# ExynosT100 register map
Vendor: SAMSUNG System LSI; Series: ARMCM4F; File version: 0.1
CPU: CM4 r1p0, little endian, MPU, FPU, 3 interrupt priority bits
Registers are 32-bit, read-write, reset 0x0 unless marked. A register's access mark holds for its fields unless they carry their own. Offsets are from the block's base; [hi:lo] are bit positions; {n}, {i} and the like mark numbered series.

## CRC — CRC Calculators
Base 0x40010000
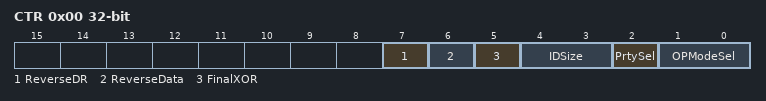
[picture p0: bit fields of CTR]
0x00 CTR — CRC Calculation Control Register
  [7] ReverseDR — Reverse CRC Result before Final XOR
  [6] ReverseData — Reverse Data Byte
  [5] FinalXOR — CRC final XOR value control 0 = Final XOR value is 0x0000_0000 1 = Final XOR value is 0xFFFF_FFFF (CRC32) or 0xFFFF (CRC16)
  [4:3] IDSize — These bits are used to select the size of input data
  [2] PrtySel — Parity Mode Control
  [1:0] OPModeSel — This bit is used to select CRC
0x04 IDR wo — Offset: 0x0004 Input data register
  [31:0] Value — These bits are input data to calculate the CRC bits
0x08 DR — Offset: 0x0008 data register
  [31:0] Value — These bits are output data buffer for calculate CRC before post processing.
0x0C ODR ro — Offset: 0x000C Output data register
  [31:0] Value — CRC bits that is calculated by hardware

## GPIO — General-Purpose Input Output
Base 0x40023000
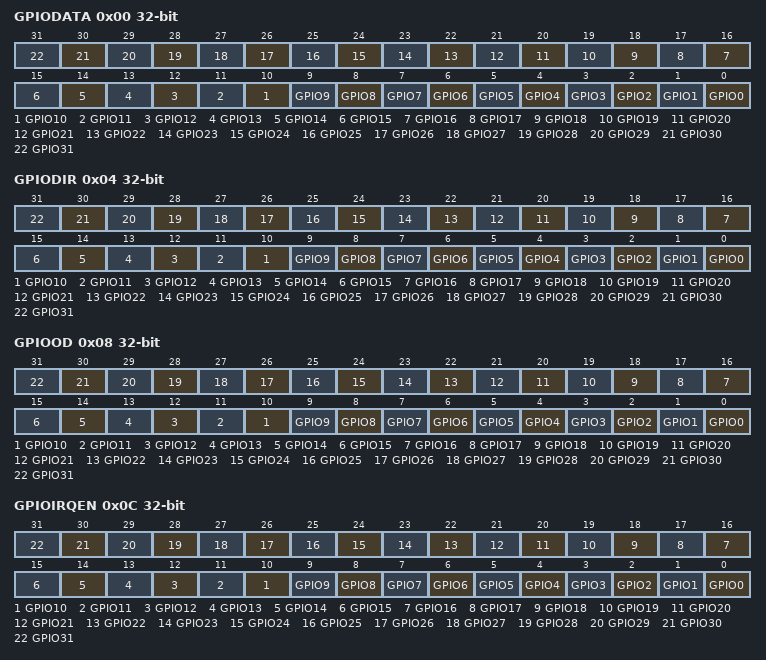
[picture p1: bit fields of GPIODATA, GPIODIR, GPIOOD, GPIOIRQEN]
0x00 GPIODATA — Read current state or set GPIO pins Input mode 0 = Associated GPIO is low 1 = Associated GPIO is high Output mode 0 = Set associated GPIO to low 1 = Set associated GPIO to high
  [n] GPIO{n} (n=0..31)
0x04 GPIODIR — Configure GPIO direction 0 = Input mode 1 = Output mode
  [n] GPIO{n} (n=0..31)
0x08 GPIOOD — GPIO n output type selection bit 0 = Set output type to push-pull mode 1 = Set output type to open-drain mode
  [n] GPIO{n} (n=0..31)
0x0C GPIOIRQEN — GPIO n interrupt enable bit 0 = IRQ disable 1 = IRQ enable
  [n] GPIO{n} (n=0..31)
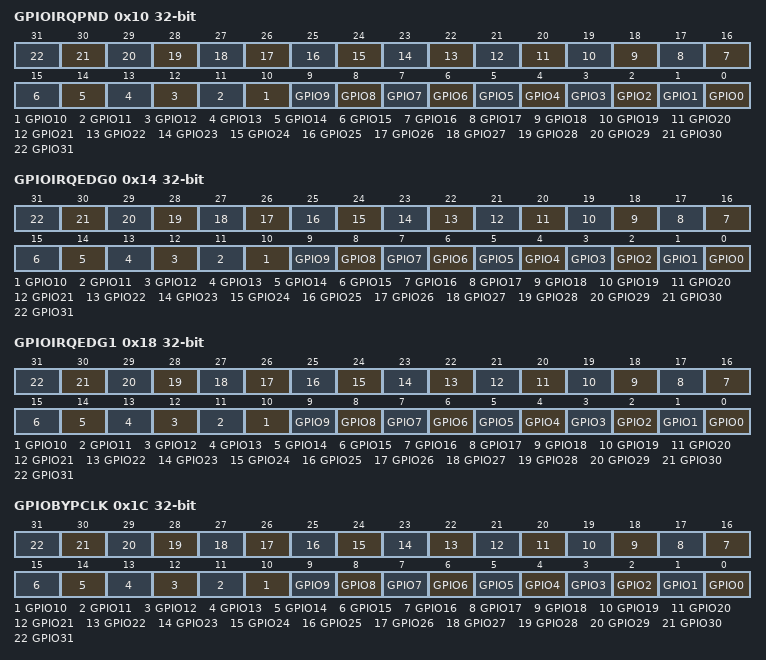
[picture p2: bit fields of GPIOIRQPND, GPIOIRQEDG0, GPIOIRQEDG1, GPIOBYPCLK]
0x10 GPIOIRQPND — GPIO n interrupt pending bit Read 0 = Associated GPIO interrupt is not occurred 1 = Associated GPIO interrupt is occurred Write (Clear only) 0 = Clear pending interrupt 1 = Reserved
  [n] GPIO{n} (n=0..31)
0x14 GPIOIRQEDG0 — GPIO0 edge type0 for IRQ GPIO IRQ egde is determined by GPIOIRQEDG1 and GPIOIRQEDG0 registers. It works by a combination of these registers. The number of GPIOs is 32. Each GPIO matches each bit. 00 = No IRQ 01 = IRQEN at negative edge 10 = IRQEN at positive edge 11 = IRQEN at both edgeGPIO0 edge type0 for IRQ
  [n] GPIO{n} (n=0..31)
0x18 GPIOIRQEDG1 — GPIO0 edge type0 for IRQ GPIO IRQ egde is determined by GPIOIRQEDG1 and GPIOIRQEDG0 registers. It works by a combination of these registers. The number of GPIOs is 32. Each GPIO matches each bit. 00 = No IRQ 01 = IRQEN at negative edge 10 = IRQEN at positive edge 11 = IRQEN at both edge
  [n] GPIO{n} (n=0..31)
0x1C GPIOBYPCLK — GPIO n bypass clock synchronization bit 0 = System clock synchronization data 1 = Asynchronization data
  [n] GPIO{n} (n=0..31)
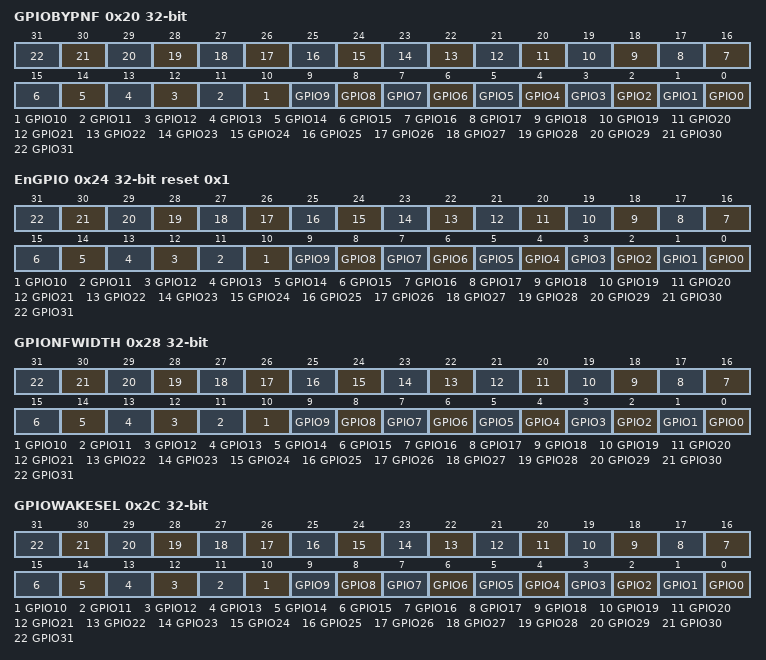
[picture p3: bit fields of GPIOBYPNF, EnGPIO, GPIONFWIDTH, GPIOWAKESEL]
0x20 GPIOBYPNF — GPIO n bypass noise filter bit 0 = Bypass 1 = 10 ns glitch free
  [n] GPIO{n} (n=0..31)
0x24 EnGPIO reset 0x1 — GPIO function enable bit All pads are MUXed with several function pads. You should enable GPIO to use the pad as GPIO. 0 = Disable 1 = Enable
  [n] GPIO{n} (n=0..31)
0x28 GPIONFWIDTH — Select GPIO noise filter width 00 = 10 ns 01 = 20 ns 10 = 30 ns 11 = 40 ns
  [n] GPIO{n} (n=0..31)
0x2C GPIOWAKESEL — GPIO wake-up source selection bit 0 = Do not use wake-up source 1 = Use wake-up source
  [n] GPIO{n} (n=0..31)

## PAD — IO PAD control
Base 0x400B0000
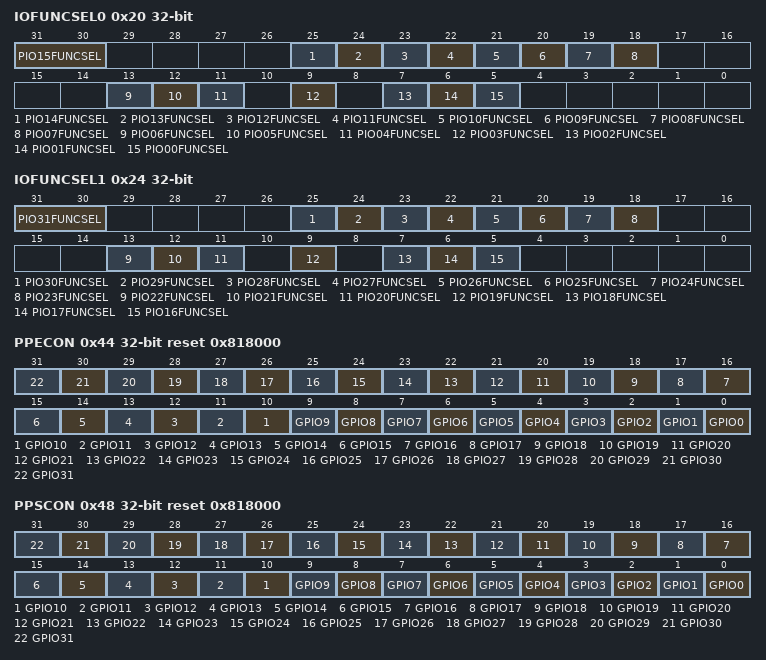
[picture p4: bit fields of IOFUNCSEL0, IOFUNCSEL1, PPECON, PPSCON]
0x20 IOFUNCSEL0 reset not defined — GPIO PAD name for I/O function selection 00 = I/O function01 01 = I/O function02 10/11 = Reserved
  [31:30] PIO15FUNCSEL — 0: ADTRNG, 1:TXD2
  [25] PIO14FUNCSEL — 0: PEI0, 1:RXD2
  [24] PIO13FUNCSEL — 0: CTS2, 1:MOSIB
  [23] PIO12FUNCSEL — 0: RTS2, 1:MISOB
  [22] PIO11FUNCSEL — 0: TPWM0, 1:NCSB
  [21] PIO10FUNCSEL — 0: MOSIB, 1:RTS0
  [20] PIO09FUNCSEL — 0: MISOB, 1:CTS0
  [19] PIO08FUNCSEL — 0: NCSB, 1:TXD2
  [18] PIO07FUNCSEL — 0: SCKB, 1:RXD2
  [13] PIO06FUNCSEL — 0: TCLK1, 1:MISOS
  [12] PIO05FUNCSEL — 0: RSVD, 1:MOSIS
  [11] PIO04FUNCSEL — 0: RTS0, 1:NCSS
  [9] PIO03FUNCSEL — 0: CTS0, 1:SCKS
  [7] PIO02FUNCSEL — 0: TCLK0, 1:SCKB
  [6] PIO01FUNCSEL — 0: TXD2, 1:SDAM0
  [5] PIO00FUNCSEL — 0: RXD2, 1:SCLM0
0x24 IOFUNCSEL1 reset not defined — I/O Function Selection Register 1
  [31:30] PIO31FUNCSEL — 0: ADTRNG, 1:TXD2
  [25] PIO30FUNCSEL — 0: PEI0, 1:RXD2
  [24] PIO29FUNCSEL — 0: CTS2, 1:MOSIB
  [23] PIO28FUNCSEL — 0: RTS2, 1:MISOB
  [22] PIO27FUNCSEL — 0: TPWM0, 1:NCSB
  [21] PIO26FUNCSEL — 0: MOSIB, 1:RTS0
  [20] PIO25FUNCSEL — 0: MISOB, 1:CTS0
  [19] PIO24FUNCSEL — 0: NCSB, 1:TXD2
  [18] PIO23FUNCSEL — 0: SCKB, 1:RXD2
  [13] PIO22FUNCSEL — 0: TCLK1, 1:MISOS
  [12] PIO21FUNCSEL — 0: RSVD, 1:MOSIS
  [11] PIO20FUNCSEL — 0: RTS0, 1:NCSS
  [9] PIO19FUNCSEL — 0: CTS0, 1:SCKS
  [7] PIO18FUNCSEL — 0: TCLK0, 1:SCKB
  [6] PIO17FUNCSEL — 0: TXD2, 1:SDAM0
  [5] PIO16FUNCSEL — 0: RXD2, 1:SCLM0
0x44 PPECON reset 0x818000 — Pad pull-up/pull-down enable The order of each bit is equal to order of PIO number. 0 = Disable 1 = Enable
  [n] GPIO{n} (n=0..31)
0x48 PPSCON reset 0x818000 — Pad pull-up / pull-down selection The order of each bit is equal to order of PIO number 0 = Pull-down enable 1 = Pull-up enable
  [n] GPIO{n} (n=0..31)
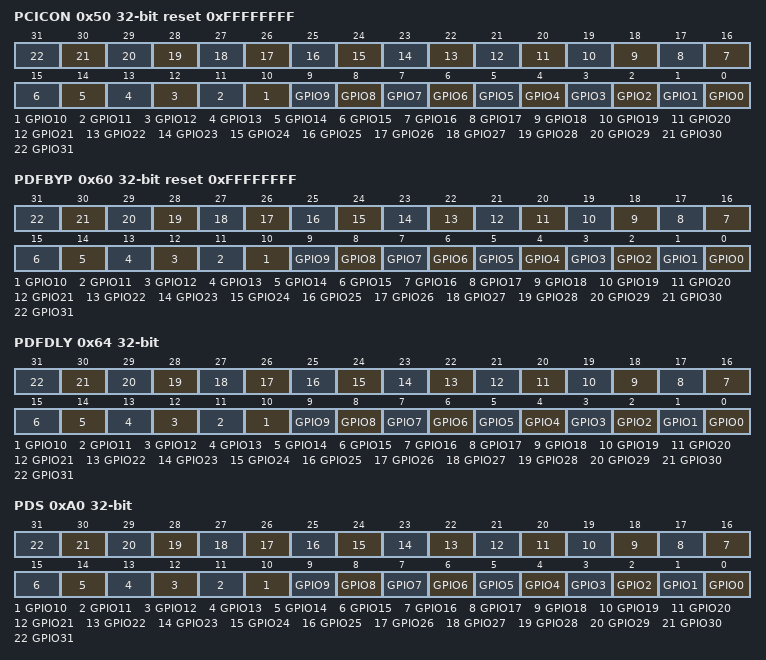
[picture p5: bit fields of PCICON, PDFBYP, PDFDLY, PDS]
0x50 PCICON reset 0xFFFFFFFF — PAD input enable The order of each bit is equal to order of PIO number 0 = Disable 1 = Enable
  [n] GPIO{n} (n=0..31)
0x60 PDFBYP reset 0xFFFFFFFF — Pad De-Glitch Filter Bypass
  [n] GPIO{n} (n=0..31)
0x64 PDFDLY — Delay Selection of PAD De-Glitch Filter
  [n] GPIO{n} (n=0..31)
0xA0 PDS — Drive Strength Selection The order of each bit is equal to order of PIO number. 0 = 2.5mA(single battery / double battery) 1 = 3.5mA(single battery) or 5mA(double battery)
  [n] GPIO{n} (n=0..31)
